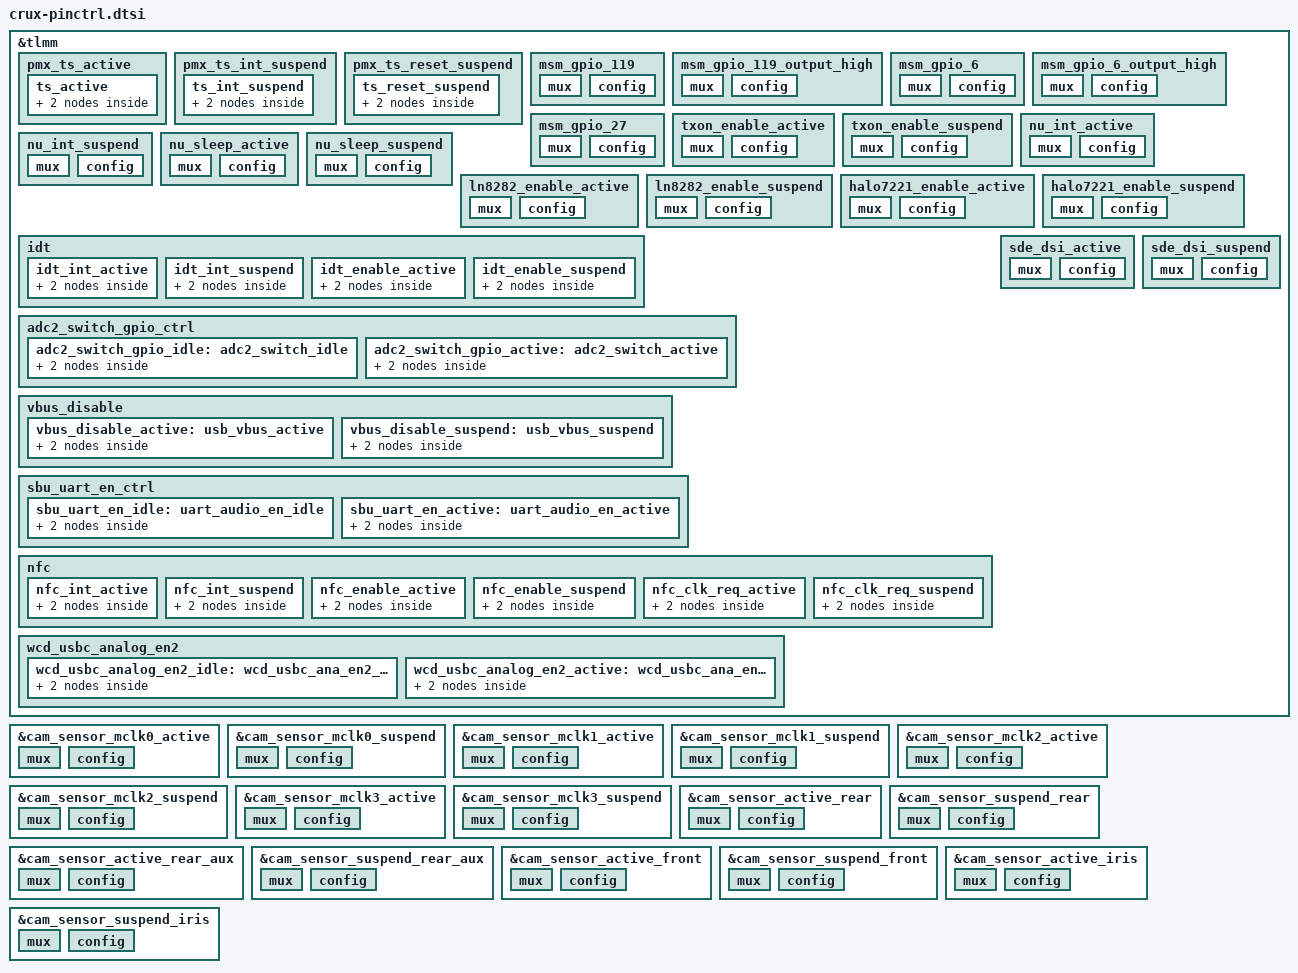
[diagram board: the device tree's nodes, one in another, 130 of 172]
/*for F1X pinctrl*/

&tlmm {
	pmx_ts_active {
		ts_active: ts_active {
				mux {
					pins = "gpio122", "gpio12", "gpio31";
					function = "gpio";
				};
				config {
					pins = "gpio122", "gpio12", "gpio31";
					drive-strength = <8>;
					bias-pull-up;
				};
		};
	};

	pmx_ts_int_suspend {
		ts_int_suspend: ts_int_suspend {
			mux {
				pins = "gpio122";
				function = "gpio";
			};
			config {
				pins = "gpio122";
				drive-strength = <2>;
				bias-pull-down;
				input-enable;
			};
		};
	};

	pmx_ts_reset_suspend {
		ts_reset_suspend: ts_reset_suspend {
			mux {
				pins = "gpio12";
				function = "gpio";
			};
			config {
				pins = "gpio12";
				drive-strength = <2>;
				bias-disable;
				output-low;
			};
		};
	};

	/* GPIO_119 : FP_RESET_N */
	msm_gpio_119: msm_gpio_119 {
		mux {
			 pins = "gpio119";
			 function = "gpio";
		};

		config {
			pins = "gpio119";
			drive-strength = <2>;
			bias-disable;
			output-low;
		};
	};

	/* GPIO_119 : FP_RESET_N, state device active*/
	msm_gpio_119_output_high: msm_gpio_119_output_high {
		mux {
			pins = "gpio119";
			function = "gpio";
		};

		config {
			pins = "gpio119";
			drive-strength = <2>;
			bias-disable;
			output-high;
		};
	};

	/* GPIO_6 : AW8697_RESET_N */
	msm_gpio_6: msm_gpio_6 {
		mux {
			 pins = "gpio6";
			 function = "gpio";
		};

		config {
			pins = "gpio6";
			drive-strength = <2>;
			bias-disable;
			output-low;
		};
	};
	/* GPIO_6 : AW8697_RESET_N, state device active*/
	msm_gpio_6_output_high: msm_gpio_6_output_high {
		mux {
			pins = "gpio6";
			function = "gpio";
		};

		config {
			pins = "gpio6";
			drive-strength = <2>;
			bias-disable;
			output-high;
		};
	};
	/* GPIO_27 : AW8697_INTERRUPT_N */
	msm_gpio_27: msm_gpio_27 {
		mux {
			 pins = "gpio27";
			 function = "gpio";
		};

		config {
			pins = "gpio27";
			drive-strength = <2>;
			bias-pull-up;
			input-enable;
		};
	};

	txon_enable_active: txon_enable_active {
		/* active state */
		mux {
			pins = "gpio130";
			function = "gpio";
		};

		config {
			pins = "gpio130";
			drive-strength = <2>;
			bias-pull-up;
			output-high;
		};
	};

	txon_enable_suspend: txon_enable_suspend {
		/* sleep state */
		mux {
			pins = "gpio130";
			function = "gpio";
		};

		config {
			pins = "gpio130";
			drive-strength = <2>;
			bias-disable;
			bias-pull-down;
			output-low;
		};
	};
	nu_int_active: nu_int_active {
		/* active state */
		mux {
			pins = "gpio90";
			function = "gpio";
		};

		config {
			pins = "gpio90";
			drive-strength = <2>;
			bias-pull-up;
			input-enable;
		};
	};

	nu_int_suspend: nu_int_suspend {
		/* sleep state */
		mux {
			pins = "gpio90";
			function = "gpio";
		};

		config {
			pins = "gpio90";
			drive-strength = <2>;
			bias-pull-up;
			input-enable;
		};
	};
	nu_sleep_active: nu_sleep_active {
		/* active state */
		mux {
			pins = "gpio7";
			function = "gpio";
		};

		config {
			pins = "gpio7";
			drive-strength = <2>;
			bias-disable;
			bias-pull-down;
			output-low;
		};
	};

	nu_sleep_suspend: nu_sleep_suspend {
		/* sleep state */
		mux {
			pins = "gpio7";
			function = "gpio";
		};

		config {
			pins = "gpio7";
			drive-strength = <2>;
			bias-disable;
			bias-pull-down;
			output-low;
		};
	};

	ln8282_enable_active: ln8282_enable_active {
		mux {
			pins = "gpio41";
			function = "gpio";
		};

		config {
			pins = "gpio41";
			drive-strength = <2>;
			bias-pull-down;
			output-low;
		};
	};
	ln8282_enable_suspend: ln8282_enable_suspend {
		mux {
			pins = "gpio41";
			function = "gpio";
		};

		config {
			pins = "gpio41";
			drive-strength = <2>;
			bias-pull-up;
			output-high;
		};
	};

	halo7221_enable_active: halo7221_enable_active {
		mux {
			pins = "gpio41";
			function = "gpio";
		};

		config {
			pins = "gpio41";
			drive-strength = <2>;
			bias-pull-up;
			output-high;
		};
	};
	halo7221_enable_suspend: halo7221_enable_suspend {
		mux {
			pins = "gpio41";
			function = "gpio";
		};

		config {
			pins = "gpio41";
			drive-strength = <2>;
			bias-pull-down;
			output-low;
		};
	};

	idt {
		idt_int_active: idt_int_active {
			/* active state */
			mux {
				pins = "gpio90";
				function = "gpio";
			};

			config {
				pins = "gpio90";
				drive-strength = <2>; /* 2 MA */
				bias-pull-up;
				input-enable;
			};
		};

		idt_int_suspend: idt_int_suspend {
			/* sleep state */
			mux {
				pins = "gpio90";
				function = "gpio";
			};

			config {
				pins = "gpio90";
				drive-strength = <2>; /* 2 MA */
				bias-pull-up;
				input-enable;
			};
		};

		idt_enable_active: idt_enable_active {
			/* active state */
			mux {
				pins = "gpio7";
				function = "gpio";
			};

			config {
				pins = "gpio7";
				drive-strength = <2>;
				bias-disable;
				bias-pull-down;
				output-low;
			};
		};

		idt_enable_suspend: idt_enable_suspend {
			/* sleep state */
			mux {
				pins = "gpio7";
				function = "gpio";
			};

			config {
				pins = "gpio7";
				drive-strength = <2>;
				bias-pull-up;
			};
		};
	};

	adc2_switch_gpio_ctrl {
		adc2_switch_gpio_idle: adc2_switch_idle {
			mux {
				pins = "gpio134";
				function = "gpio";
			};
			config {
				pins = "gpio134";
				drive-strength = <2>;
				bias-pull-down;
				output-low;
			};
		};

		adc2_switch_gpio_active: adc2_switch_active {
			mux {
				pins = "gpio134";
				function = "gpio";
			};
			config {
				pins = "gpio134";
				drive-strength = <2>;
				bias-disable;
				output-high;
			};
		};
	};

	vbus_disable {
		vbus_disable_active: usb_vbus_active {
			/* active state */
			mux {
				pins = "gpio87";
				function = "gpio";
			};

			config {
				pins = "gpio87";
				drive-strength = <2>; /* 2 MA */
				bias-pull-up;
				output-high;

			};
		};

		vbus_disable_suspend: usb_vbus_suspend {
			mux {
				pins = "gpio87";
				function = "gpio";
			};

			config {
				pins = "gpio87";
				drive-strength = <2>; /* 2 MA */
				bias-pull-down;
				output-low;
			};
		};
	};

	sbu_uart_en_ctrl {
		sbu_uart_en_idle: uart_audio_en_idle {
			mux {
				pins = "gpio25";
				function = "gpio";
			};
			config {
				pins = "gpio25";
				drive-strength = <2>;
				bias-pull-down;
				output-low;
			};
		};

		sbu_uart_en_active: uart_audio_en_active {
			mux {
				pins = "gpio25";
				function = "gpio";
			};
			config {
				pins = "gpio25";
				drive-strength = <2>;
				bias-disable;
				output-high;
			};
		};
	};

	nfc {
		nfc_int_active: nfc_int_active {
			/* active state */
			mux {
				/* GPIO 47 NFC Read Interrupt */
				pins = "gpio47";
				function = "gpio";
			};

			config {
				pins = "gpio47";
				drive-strength = <2>; /* 2 MA */
				bias-pull-up;
			};
		};

		nfc_int_suspend: nfc_int_suspend {
			/* sleep state */
			mux {
				/* GPIO 47 NFC Read Interrupt */
				pins = "gpio47";
				function = "gpio";
			};

			config {
				pins = "gpio47";
				drive-strength = <2>; /* 2 MA */
				bias-pull-up;
			};
		};

		nfc_enable_active: nfc_enable_active {
			/* active state */
			mux {
				/* 36: NFC ENABLE 42:ESE Enable */
				pins = "gpio36", "gpio48";
				function = "gpio";
			};

			config {
				pins = "gpio36", "gpio48";
				drive-strength = <2>; /* 2 MA */
				bias-pull-up;
			};
		};

		nfc_enable_suspend: nfc_enable_suspend {
			/* sleep state */
			mux {
				/* 36: NFC ENABLE 42:ESE Enable */
				pins = "gpio36", "gpio48";
				function = "gpio";
			};

			config {
				pins = "gpio36", "gpio48";
				drive-strength = <2>; /* 2 MA */
				bias-disable;
			};
		};

		nfc_clk_req_active: nfc_clk_req_active {
			/* active state */
			mux {
				/* 113: NFC CLOCK REQUEST */
				pins = "gpio113";
				function = "gpio";
			};

			config {
				pins = "gpio113";
				drive-strength = <2>; /* 2 MA */
				bias-pull-up;
			};
		};

		nfc_clk_req_suspend: nfc_clk_req_suspend {
			/* sleep state */
			mux {
				/* 113: NFC CLOCK REQUEST */
				pins = "gpio113";
				function = "gpio";
			};

			config {
				pins = "gpio113";
				drive-strength = <2>; /* 2 MA */
				bias-disable;
			};
		};
	};

	wcd_usbc_analog_en2 {
		wcd_usbc_analog_en2_idle: wcd_usbc_ana_en2_idle {
			mux {
				pins = "gpio32";
				function = "gpio";
			};
			config {
				pins = "gpio32";
				drive-strength = <2>;
				bias-pull-down;
				output-low;
			};
		};

		wcd_usbc_analog_en2_active: wcd_usbc_ana_en2_active {
			mux {
				pins = "gpio32";
				function = "gpio";
			};
			config {
				pins = "gpio32";
				drive-strength = <2>;
				bias-disable;
				output-high;
			};
		};
	};

	sde_dsi_active: sde_dsi_active {
		mux {
			pins = "gpio11";
			function = "gpio";
		};

		config {
			pins = "gpio11";
			drive-strength = <8>;   /* 8 mA */
			bias-disable = <0>;   /* no pull */
		};
	};
	sde_dsi_suspend: sde_dsi_suspend {
		mux {
			pins = "gpio11";
			function = "gpio";
		};

		config {
			pins = "gpio11";
			drive-strength = <2>;   /* 2 mA */
			bias-pull-down;         /* PULL DOWN */
		};
	};
};


//camera voltage start
&cam_sensor_mclk0_active {
	/* MCLK0 */
	mux {
		pins = "gpio13";
		function = "cam_mclk";
	};

	config {
		pins = "gpio13";
		bias-disable; /* No PULL */
		drive-strength = <4>; /* 2 MA */
	};
};

&cam_sensor_mclk0_suspend {
	/* MCLK0 */
	mux {
		pins = "gpio13";
		function = "cam_mclk";
	};

	config {
		pins = "gpio13";
		bias-pull-down; /* PULL DOWN */
		drive-strength = <4>; /* 2 MA */
	};
};

&cam_sensor_mclk1_active {
	/* MCLK1 */
	mux {
		pins = "gpio14";
		function = "cam_mclk";
	};

	config {
		pins = "gpio14";
		bias-disable; /* No PULL */
		drive-strength = <4>; /* 2 MA */
	};
};

&cam_sensor_mclk1_suspend {
	/* MCLK1 */
	mux {
		pins = "gpio14";
		function = "cam_mclk";
	};

	config {
		pins = "gpio14";
		bias-pull-down; /* PULL DOWN */
		drive-strength = <4>; /* 2 MA */
	};
};

&cam_sensor_mclk2_active {
	/* MCLK2 */
	mux {
		pins = "gpio15";
		function = "cam_mclk";
	};

	config {
		pins = "gpio15";
		bias-disable; /* No PULL */
		drive-strength = <4>; /* 2 MA */
	};
};

&cam_sensor_mclk2_suspend {
	/* MCLK2 */
	mux {
		pins = "gpio15";
		function = "cam_mclk";
	};

	config {
		pins = "gpio15";
		bias-pull-down; /* PULL DOWN */
		drive-strength = <4>; /* 2 MA */
	};
};

&cam_sensor_mclk3_active {
	/* MCLK3 */
	mux {
		pins = "gpio16";
		function = "cam_mclk";
	};

	config {
		pins = "gpio16";
		bias-disable; /* No PULL */
		drive-strength = <4>; /* 2 MA */
	};
};

&cam_sensor_mclk3_suspend {
	/* MCLK3 */
	mux {
		pins = "gpio16";
		function = "cam_mclk";
	};

	config {
		pins = "gpio16";
		bias-pull-down; /* PULL DOWN */
		drive-strength = <4>; /* 2 MA */
	};
};

&cam_sensor_active_rear {
	/* RESET REAR2 */
	mux {
		pins = "gpio30", "gpio59";
		function = "gpio";
	};

	config {
		pins = "gpio30", "gpio59";
		bias-disable; /* No PULL */
		drive-strength = <2>; /* 2 MA */
	};
};

&cam_sensor_suspend_rear {
	/* RESET REAR2 */
	mux {
		pins = "gpio30", "gpio59";
		function = "gpio";
	};

	config {
		pins = "gpio30", "gpio59";
		bias-pull-down; /* PULL DOWN */
		drive-strength = <2>; /* 2 MA */
		output-low;
	};
};

&cam_sensor_active_rear_aux {
	/* RESET REARAUX, VANA REARAUX */
	mux {
		pins = "gpio23", "gpio29";
		function = "gpio";
	};

	config {
		pins = "gpio23", "gpio29";
		bias-disable; /* No PULL */
		drive-strength = <2>; /* 2 MA */
	};
};

&cam_sensor_suspend_rear_aux {
	/* RESET REARAUX, VANA REARAUX */
	mux {
		pins = "gpio23", "gpio29";
		function = "gpio";
	};

	config {
		pins = "gpio23", "gpio29";
		bias-pull-down; /* PULL DOWN */
		drive-strength = <2>; /* 2 MA */
		output-low;
	};
};

&cam_sensor_active_front {
	/* RESET FRONT, VANA FRONT*/
	mux {
		//pins = "gpio54","gpio132","gpio118";
		pins = "gpio54","gpio118";
		function = "gpio";
	};

	config {
		//pins = "gpio54","gpio132","gpio118";
		pins = "gpio54","gpio118";
		bias-disable; /* No PULL */
		drive-strength = <2>; /* 2 MA */
	};
};

&cam_sensor_suspend_front {
	/* RESET FRONT, VANA FRONT*/
	mux {
		//pins = "gpio54","gpio132","gpio118";
		pins = "gpio54","gpio118";
		function = "gpio";
	};

	config {
		//pins = "gpio54","gpio132","gpio118";
		pins = "gpio54","gpio118";
		bias-pull-down; /* PULL DOWN */
		drive-strength = <2>; /* 2 MA */
		output-low;
	};
};

&cam_sensor_active_iris {
	/* RESET ULTRA, VANA VDIG ULTRA*/
	mux {
		pins = "gpio28","gpio94";
		function = "gpio";
	};

	config {
		pins = "gpio28","gpio94";
		bias-disable; /* No PULL */
		drive-strength = <2>; /* 2 MA */
	};
};

&cam_sensor_suspend_iris {
	/* RESET ULTRA, VANA VDIG ULTRA*/
	mux {
		pins = "gpio28","gpio94";
		function = "gpio";
	};

	config {
		pins = "gpio28","gpio94";
		bias-pull-down; /* PULL DOWN */
		drive-strength = <2>; /* 2 MA */
		output-low;
	};
};

//camera voltage end
